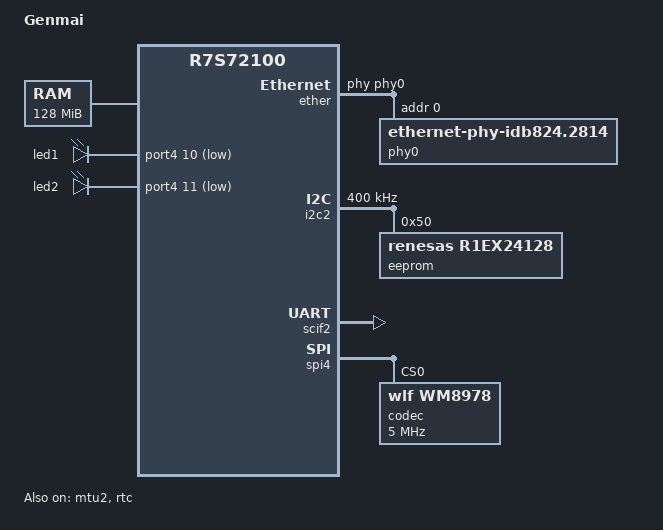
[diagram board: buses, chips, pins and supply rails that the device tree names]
/dts-v1/;
#include "r7s72100.dtsi"
#include <dt-bindings/gpio/gpio.h>
#include <dt-bindings/pinctrl/r7s72100-pinctrl.h>
/ {
	model = "Genmai";
	compatible = "renesas,genmai", "renesas,r7s72100";
	aliases {
		serial0 = &scif2;
	};
	chosen {
		bootargs = "ignore_loglevel rw root=/dev/nfs ip=on";
		stdout-path = "serial0:115200n8";
	};
	memory@8000000 {
		device_type = "memory";
		reg = <0x08000000 0x08000000>;
	};
	lbsc {
		#address-cells = <1>;
		#size-cells = <1>;
	};
	leds {
		status = "okay";
		compatible = "gpio-leds";
		led1 {
			gpios = <&port4 10 GPIO_ACTIVE_LOW>;
		};
		led2 {
			gpios = <&port4 11 GPIO_ACTIVE_LOW>;
		};
	};
};
&pinctrl {
	scif2_pins: serial2 {
		pinmux = <RZA1_PINMUX(3, 0, 6)>, <RZA1_PINMUX(3, 2, 4)>;
	};
	i2c2_pins: i2c2 {
		pinmux = <RZA1_PINMUX(1, 4, 1)>, <RZA1_PINMUX(1, 5, 1)>;
	};
	ether_pins: ether {
		pinmux = <RZA1_PINMUX(1, 14, 4)>, 
			 <RZA1_PINMUX(5, 9, 2)>,  
			 <RZA1_PINMUX(3, 3, 2)>,  
			 <RZA1_PINMUX(3, 4, 2)>,  
			 <RZA1_PINMUX(3, 5, 2)>,  
			 <RZA1_PINMUX(3, 6, 2)>,  
			 <RZA1_PINMUX(2, 0, 2)>,  
			 <RZA1_PINMUX(2, 1, 2)>,  
			 <RZA1_PINMUX(2, 2, 2)>,  
			 <RZA1_PINMUX(2, 3, 2)>,  
			 <RZA1_PINMUX(2, 4, 2)>,  
			 <RZA1_PINMUX(2, 5, 2)>,  
			 <RZA1_PINMUX(2, 6, 2)>,  
			 <RZA1_PINMUX(2, 7, 2)>,  
			 <RZA1_PINMUX(2, 8, 2)>,  
			 <RZA1_PINMUX(2, 9, 2)>,  
			 <RZA1_PINMUX(2, 10, 2)>, 
			 <RZA1_PINMUX(2, 11, 2)>; 
	};
};
&extal_clk {
	clock-frequency = <13330000>;
};
&usb_x1_clk {
	clock-frequency = <48000000>;
};
&rtc_x1_clk {
	clock-frequency = <32768>;
};
&mtu2 {
	status = "okay";
};
&ether {
	pinctrl-names = "default";
	pinctrl-0 = <&ether_pins>;
	status = "okay";
	renesas,no-ether-link;
	phy-handle = <&phy0>;
	phy0: ethernet-phy@0 {
		compatible = "ethernet-phy-idb824.2814",
			     "ethernet-phy-ieee802.3-c22";
		reg = <0>;
	};
};
&i2c2 {
	status = "okay";
	clock-frequency = <400000>;
	pinctrl-names = "default";
	pinctrl-0 = <&i2c2_pins>;
	eeprom@50 {
		compatible = "renesas,r1ex24128", "atmel,24c128";
		reg = <0x50>;
		pagesize = <64>;
	};
};
&rtc {
	status = "okay";
};
&scif2 {
	pinctrl-names = "default";
	pinctrl-0 = <&scif2_pins>;
	status = "okay";
};
&spi4 {
	status = "okay";
	codec: codec@0 {
		compatible = "wlf,wm8978";
		reg = <0>;
		spi-max-frequency = <5000000>;
	};
};
